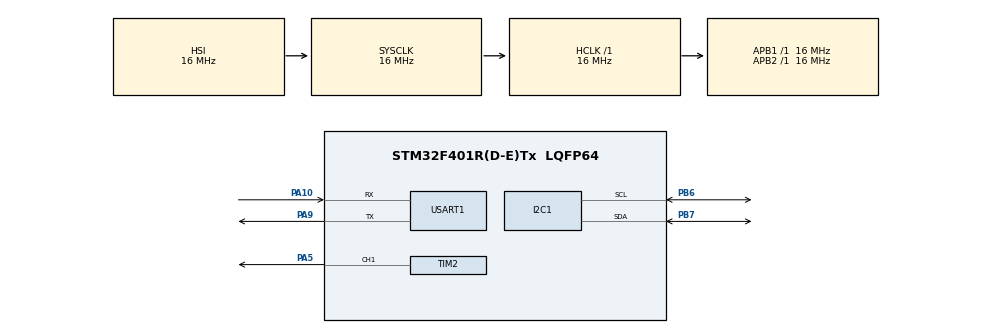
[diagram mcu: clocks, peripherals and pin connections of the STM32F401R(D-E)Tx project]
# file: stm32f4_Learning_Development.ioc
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I2C1.I2C_Mode=I2C_Fast
Mcu.Family=STM32F4
Mcu.Name=STM32F401R(D-E)Tx
Mcu.Package=LQFP64
NVIC.PriorityGroup=NVIC_PRIORITYGROUP_4
NVIC.USART1_IRQn=true\:0\:0\:false\:false\:true\:true\:true\:true
PA10.Mode=Asynchronous
PA10.Signal=USART1_RX
PA5.Signal=S_TIM2_CH1_ETR
PA9.Mode=Asynchronous
PA9.Signal=USART1_TX
PB6.Mode=I2C
PB6.Signal=I2C1_SCL
PB7.Mode=I2C
PB7.Signal=I2C1_SDA
ProjectManager.HeapSize=0x200
ProjectManager.StackSize=0x400
ProjectManager.TargetToolchain=STM32CubeIDE
RCC.AHBFreq_Value=16000000
RCC.APB1Freq_Value=16000000
RCC.APB2Freq_Value=16000000
RCC.CortexFreq_Value=16000000
RCC.HSE_VALUE=25000000
RCC.HSI_VALUE=16000000
RCC.LSE_VALUE=32768
RCC.SYSCLKFreq_VALUE=16000000
RCC.VCOOutputFreq_Value=192000000
SH.S_TIM2_CH1_ETR.0=TIM2_CH1,PWM Generation1 CH1
TIM10.Prescaler=16-1
TIM2.Channel-PWM\ Generation1\ CH1=TIM_CHANNEL_1
TIM2.Period=1000000
TIM2.Prescaler=16-1
USART1.VirtualMode=VM_ASYNC
VP_TIM10_VS_ClockSourceINT.Mode=Enable_Timer
VP_TIM2_VS_ClockSourceINT.Mode=Internal
board=custom

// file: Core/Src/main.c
/* USER CODE BEGIN Header */
/**
  ******************************************************************************
  * @file           : main.c
  * @brief          : Main program body
  ******************************************************************************
  * @attention
  *
  * Copyright (c) 2024 STMicroelectronics.
  * All rights reserved.
  *
  * This software is licensed under terms that can be found in the LICENSE file
  * in the root directory of this software component.
  * If no LICENSE file comes with this software, it is provided AS-IS.
  *
  ******************************************************************************
  */
/* USER CODE END Header */
#include "main.h"
#include "i2c.h"
#include "tim.h"
#include "usart.h"
#include "gpio.h"

/* USER CODE BEGIN Includes */
#include "app_main.h"

/* USER CODE END Includes */

void SystemClock_Config(void);

/* USER CODE BEGIN 0 */
uint8_t dataRead[64];

uint8_t dataWrite[64];

/* USER CODE END 0 */

int main(void)
{

  /* MCU Configuration--------------------------------------------------------*/

  /* Reset of all peripherals, Initializes the Flash interface and the Systick. */
  HAL_Init();

  /* Configure the system clock */
  SystemClock_Config();

  /* Initialize all configured peripherals */
  MX_GPIO_Init();
  MX_USART1_UART_Init();
  MX_TIM10_Init();
  MX_TIM2_Init();
  MX_I2C1_Init();
  /* USER CODE BEGIN 2 */
  /* TIM10 is used to count time elapsed between two events in microsecond*/
  HAL_TIM_Base_Start(&htim10);
  HAL_TIM_PWM_Start(&htim2, TIM_CHANNEL_1);

  /* prescalar (16 - 1) [(Counter Compare 500000) / (auto reload register 1000000)] */
  __HAL_TIM_SET_COMPARE(&htim2,TIM_CHANNEL_1,500000); /* Duty cycle of 50 %*/
  /* __HAL_TIM_GET_COUNTER(&htim10); */

  for (int i=0; i<64; i++)
  {
	  dataWrite[i] = i;
  }

//  EEPROM_Write(7, 50, dataWrite, 64);
//  HAL_Delay(10);
  EEPROM_Read(7, 0, dataRead, 64);
  EEPROM_Read(8, 0, dataRead, 64);

  /* USER CODE END 2 */

  /* Infinite loop */
  while (1)
  {

  }
}

void SystemClock_Config(void)
{
  RCC_OscInitTypeDef RCC_OscInitStruct = {0};
  RCC_ClkInitTypeDef RCC_ClkInitStruct = {0};

  /** Configure the main internal regulator output voltage
  */
  __HAL_RCC_PWR_CLK_ENABLE();
  __HAL_PWR_VOLTAGESCALING_CONFIG(PWR_REGULATOR_VOLTAGE_SCALE2);

  /** Initializes the RCC Oscillators according to the specified parameters
  * in the RCC_OscInitTypeDef structure.
  */
  RCC_OscInitStruct.OscillatorType = RCC_OSCILLATORTYPE_HSI;
  RCC_OscInitStruct.HSIState = RCC_HSI_ON;
  RCC_OscInitStruct.HSICalibrationValue = RCC_HSICALIBRATION_DEFAULT;
  RCC_OscInitStruct.PLL.PLLState = RCC_PLL_NONE;
  if (HAL_RCC_OscConfig(&RCC_OscInitStruct) != HAL_OK)
  {
    Error_Handler();
  }

  /** Initializes the CPU, AHB and APB buses clocks
  */
  RCC_ClkInitStruct.ClockType = RCC_CLOCKTYPE_HCLK|RCC_CLOCKTYPE_SYSCLK
                              |RCC_CLOCKTYPE_PCLK1|RCC_CLOCKTYPE_PCLK2;
  RCC_ClkInitStruct.SYSCLKSource = RCC_SYSCLKSOURCE_HSI;
  RCC_ClkInitStruct.AHBCLKDivider = RCC_SYSCLK_DIV1;
  RCC_ClkInitStruct.APB1CLKDivider = RCC_HCLK_DIV1;
  RCC_ClkInitStruct.APB2CLKDivider = RCC_HCLK_DIV1;

  if (HAL_RCC_ClockConfig(&RCC_ClkInitStruct, FLASH_LATENCY_0) != HAL_OK)
  {
    Error_Handler();
  }
}

void Error_Handler(void)
{
  __disable_irq();
  while (1)
  {
  }
}
